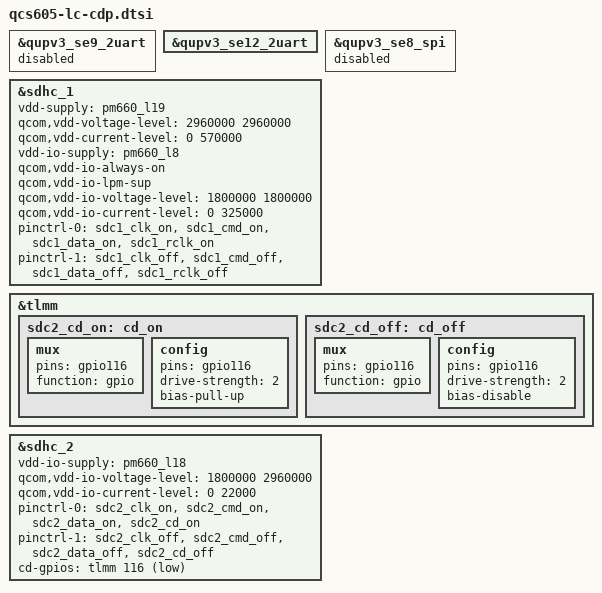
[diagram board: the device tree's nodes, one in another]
/*
 * Copyright (c) 2018, The Linux Foundation. All rights reserved.
 *
 * This program is free software; you can redistribute it and/or modify
 * it under the terms of the GNU General Public License version 2 and
 * only version 2 as published by the Free Software Foundation.
 *
 * This program is distributed in the hope that it will be useful,
 * but WITHOUT ANY WARRANTY; without even the implied warranty of
 * MERCHANTABILITY or FITNESS FOR A PARTICULAR PURPOSE.  See the
 * GNU General Public License for more details.
 */

#include "qcs605-lc-pmic-overlay.dtsi"

&qupv3_se9_2uart {
	status = "disabled";
};

&qupv3_se12_2uart {
	status = "ok";
};

&qupv3_se8_spi {
	status = "disabled";
};

&sdhc_1 {
	vdd-supply = <&pm660_l19>;
	qcom,vdd-voltage-level = <2960000 2960000>;
	qcom,vdd-current-level = <0 570000>;

	vdd-io-supply = <&pm660_l8>;
	qcom,vdd-io-always-on;
	qcom,vdd-io-lpm-sup;
	qcom,vdd-io-voltage-level = <1800000 1800000>;
	qcom,vdd-io-current-level = <0 325000>;

	pinctrl-names = "active", "sleep";
	pinctrl-0 = <&sdc1_clk_on  &sdc1_cmd_on &sdc1_data_on &sdc1_rclk_on>;
	pinctrl-1 = <&sdc1_clk_off &sdc1_cmd_off &sdc1_data_off &sdc1_rclk_off>;

	status = "ok";
};

&tlmm {
	sdc2_cd_on: cd_on {
		mux {
			pins = "gpio116";
			function = "gpio";
		};

		config {
			pins = "gpio116";
			drive-strength = <2>;
			bias-pull-up;
			};
		};

	sdc2_cd_off: cd_off {
		mux {
			pins = "gpio116";
			function = "gpio";
		};

		config {
			pins = "gpio116";
			drive-strength = <2>;
			bias-disable;
			};
	};
};

&sdhc_2 {
	/* VDD external regulator is enabled/disabled by pm660_l18 regulator */
	vdd-io-supply = <&pm660_l18>;
	qcom,vdd-io-voltage-level = <1800000 2960000>;
	qcom,vdd-io-current-level = <0 22000>;

	pinctrl-names = "active", "sleep";
	pinctrl-0 = <&sdc2_clk_on &sdc2_cmd_on &sdc2_data_on &sdc2_cd_on>;
	pinctrl-1 = <&sdc2_clk_off &sdc2_cmd_off &sdc2_data_off &sdc2_cd_off>;

	cd-gpios = <&tlmm 116 0x1>;

	status = "ok";
};
